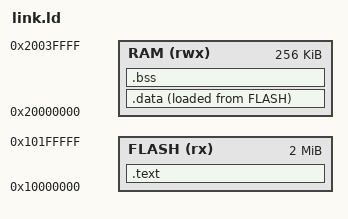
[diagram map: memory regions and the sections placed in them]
MEMORY
{
    FLASH (rx)  : ORIGIN = 0x10000000, LENGTH = 2048K
    RAM   (rwx) : ORIGIN = 0x20000000, LENGTH = 256K
}

_estack = ORIGIN(RAM) + LENGTH(RAM);

SECTIONS
{
    .text : {
        KEEP(*(.vectors))
        *(.text*)
        *(.rodata*)
    } > FLASH

    .data : {
        _sdata = .;
        *(.data*)
        _edata = .;
    } > RAM AT > FLASH
    _sidata = LOADADDR(.data);

    .bss : {
        _sbss = .;
        *(.bss*)
        *(COMMON)
        _ebss = .;
    } > RAM
}   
